VERSION ""

NS_ :

BS_: 500

BU_: Vector__XXX

BO_ 258 MSG_102: 8 Vector__XXX
 SG_ Steering_Angle : 48|16@0+ (-0.5,2046) [-1000|1000] "��" Vector__XXX

BO_ 264 MSG_108: 8 Vector__XXX
 SG_ Engine_Speed : 48|16@0+ (1,0) [0|10000] "rpm" Vector__XXX

BO_ 284 MSG_11C: 8 Vector__XXX
 SG_ Indicated_Vehicle_Speed_kph : 16|16@0+ (0.0078125,0) [0|511.984375] "km/h" Vector__XXX
 SG_ Indicated_Vehicle_Speed_mph : 16|16@0+ (0.0048515625,0) [0|317.942296875] "mph" Vector__XXX

BO_ 288 MSG_120: 7 Vector__XXX
 SG_ Accelerator_Pedal_Position : 16|8@1+ (0.4,0) [0|100] "%" Vector__XXX

BO_ 294 MSG_126: 8 Vector__XXX
 SG_ Yaw_Rate : 16|12@0+ (0.08,-163.84) [-163.84|163.68] "��/s" Vector__XXX
 SG_ Indicated_Longitudinal_Acceleration : 32|12@0+ (0.02,-40.96) [-40.96|40.92] "m/s��" Vector__XXX
 SG_ Indicated_Lateral_Acceleration : 48|12@0+ (0.02,-40.96) [-40.96|40.92] "m/s��" Vector__XXX

BO_ 320 MSG_140: 8 Vector__XXX
 SG_ Brake_Position : 2|2@1+ (1,0) [0|3] "on/off" Vector__XXX

BO_ 331 MSG_14B: 8 Vector__XXX
 SG_ Brake_Pressure : 48|11@0+ (0.1,0) [0|200] "bar" Vector__XXX

BO_ 344 MSG_158: 8 Vector__XXX
 SG_ Wheel_Speed_RR_kph : 0|14@0+ (0.06762,0) [0|13187.51] "km/h" Vector__XXX
 SG_ Wheel_Speed_RR_mph : 0|14@0+ (0.042,0) [0|8191] "mph" Vector__XXX
 SG_ Wheel_Speed_RL_kph : 16|14@0+ (0.06762,0) [0|13187.51] "km/h" Vector__XXX
 SG_ Wheel_Speed_RL_mph : 16|14@0+ (0.042,0) [0|8191] "mph" Vector__XXX
 SG_ Wheel_Speed_FR_kph : 32|14@0+ (0.06762,0) [0|13187.51] "km/h" Vector__XXX
 SG_ Wheel_Speed_FR_mph : 32|14@0+ (0.042,0) [0|8191] "mph" Vector__XXX
 SG_ Wheel_Speed_FL_kph : 48|14@0+ (0.06762,0) [0|13187.51] "km/h" Vector__XXX
 SG_ Wheel_Speed_FL_mph : 48|14@0+ (0.042,0) [0|8191] "mph" Vector__XXX

BO_ 384 MSG_180: 8 Vector__XXX
 SG_ Air_Temperature : 0|8@1+ (1,-40) [-40|214] "��C" Vector__XXX
 SG_ Coolant_Temperature : 8|8@1+ (1,-40) [-40|214] "��C" Vector__XXX

BO_ 512 MSG_200: 8 Vector__XXX
 SG_ Battery_Voltage : 48|8@1+ (0.1,0) [5|18] "V" Vector__XXX

BO_ 672 MSG_2A0: 8 Vector__XXX
 SG_ Oil_Pressure : 16|8@1+ (4,0) [0|1016] "kPaG" Vector__XXX
 SG_ Oil_Temperature : 24|8@1+ (1,-40) [-40|160] "��C" Vector__XXX

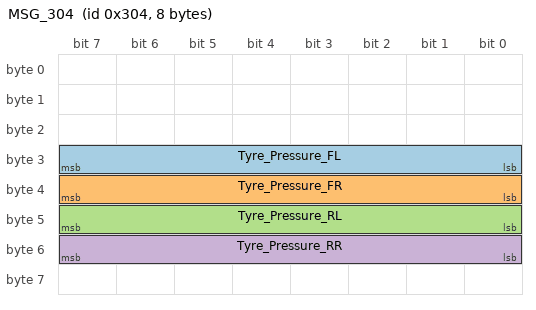
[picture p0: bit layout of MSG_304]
BO_ 772 MSG_304: 8 Vector__XXX
 SG_ Tyre_Pressure_FL : 24|8@1+ (1,0) [0|126] "psi" Vector__XXX
 SG_ Tyre_Pressure_FR : 32|8@1+ (1,0) [0|126] "psi" Vector__XXX
 SG_ Tyre_Pressure_RL : 40|8@1+ (1,0) [0|126] "psi" Vector__XXX
 SG_ Tyre_Pressure_RR : 48|8@1+ (1,0) [0|126] "psi" Vector__XXX
